# haltium_cellcore register map
Vendor: Nordic Semiconductor; Series: nRFHaltium; File version: 1
CPU: CM33 r0p4, little endian, MPU, FPU, 3 interrupt priority bits, 480 interrupts
Registers are 32-bit, read-write, reset 0x0 unless marked. A register's access mark holds for its fields unless they carry their own. Offsets are from the block's base; [hi:lo] are bit positions; lines under a group give offsets from that group; {n}, {i} and the like mark numbered series.

## RAMC00_NS — RAM Controller 0
Base 0x44006000
Same registers: RAMC00_S 0x54006000
0x500 WAITSTATES — Waitstates for read operations.
  [0] WAITSTATES — Number of waitstates for a read from the RAM.
0x600 SECBASE — Base address for secure access area.
  [31:0] ADDR — Base address
0x604 SECENABLE — Enable secure access restrictions.
  [0] ENABLE — Enable secure access restrictions
    0=Disable (Secure access restrictions disabled); 1=Enable (Secure access restrictions enabled)

## TRACEDELAYREG_NS — Trace delay register 0
Base 0x4400B000
Same registers: TRACEDELAYREG_S 0x5400B000
0x504 DELAYREGCONFIG — Configuration register for DELAYREG delay
  [4:0] DELAYREGCONFIG — Register write delay, configurable between 0 and 31 clock cycles. Delay between apbPEnable and apbPReady is adjusted to the configured value, except for the small values, when minimum interconnect delay exist.
0x600 DELAYREG wo — Dummy register with adjustable write delay. Occupies 0x100 address range i.e. 256bytes. This space emulates the extended stimulus port area of ARM Coresight STM.
  [31:0] DELAYREG — Dummy register with adjustable write delay

## PCGCS0_S — PCGCSlave 0
Base 0x5400C000
Same registers: PCGCS1_S 0x54018000, PCGCS3_S 0x54036000
0x78 TRIGZEROPENALTY — Trigger zero penalty
  [0] TRIGGER
    1=Enable (Trigger zero penalty)
0x7C TRIGFULLPENALTY — Trigger full penalty
  [0] TRIGGER
    1=Enable (Trigger full penalty)
{0xC00+4i} PENALTY[{i}] (i=0..1) — Description collection: Penalty level for power/clock pair n
  [7:0] PENALTY — Penalty level
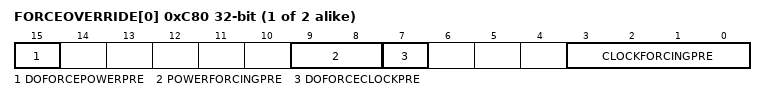
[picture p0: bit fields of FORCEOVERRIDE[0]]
{0xC80+4i} FORCEOVERRIDE[{i}] (i=0..1) — Description collection: Force override of power/clock pair n
  [15] DOFORCEPOWERPRE, [9:8] POWERFORCINGPRE, [7] DOFORCECLOCKPRE, [3:0] CLOCKFORCINGPRE

## PCGCM0_S — PCGC Master 0
Base 0x5400D000
Same registers: PCGCM1_S 0x54019000, PCGCM3_S 0x54037000
{0xE0+4i} SETPWRCONTHRESHOLDBASE[{i}] (i=0..2) — Description collection: Set power consumption threshold base for power source / regulator n
  [3:0] SETPWRCONTHRESHOLDBASE
{0x100+4i} SETPOWERCONSUMPTIONBASE[{i}] (i=0..1) — Description collection: Set power consumption base for power/clock pair n
  [3:0] POWERREQUIREMENT
0xC00 UNLOCKBACKDOORS
  [15:0] UNLOCKBACKDOORS — Write: 0x00009375 to lock/unlock backdoors Read: 0x00000001 if backdoors is enabled Read: 0x00000000 if backdoors is disabled
0xC04 ENABLEPOWERREGFORCE
  [2:0] ENABLEPOWERREGFORCE
0xC08 POWERREGFORCE — Force reg
  [2:0] POWERREGFORCEREG
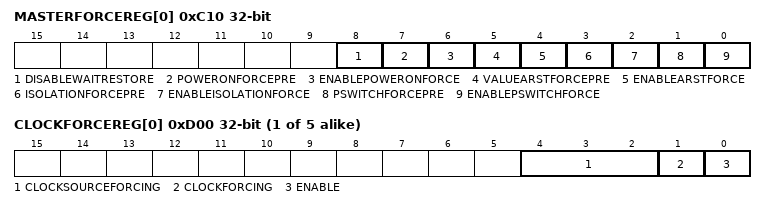
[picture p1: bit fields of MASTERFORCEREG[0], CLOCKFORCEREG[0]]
{0xC10+4i} MASTERFORCEREG[{i}] (i=0..0) — Description collection: Force reg
  [8] DISABLEWAITRESTORE — Turn off waiting for arst deactivation before retention restore
    1=Disable (Turn off waiting for arst deactivation before retention restore); 0=Enable (Wait for arst deactivation before retention restore)
  [7] POWERONFORCEPRE
  [6] ENABLEPOWERONFORCE
  [5] VALUEARSTFORCEPRE
  [4] ENABLEARSTFORCE
  [3] ISOLATIONFORCEPRE
  [2] ENABLEISOLATIONFORCE
  [1] PSWITCHFORCEPRE
  [0] ENABLEPSWITCHFORCE
{0xD00+4i} CLOCKFORCEREG[{i}] (i=0..4) — Description collection: Force clock n
  [4:2] CLOCKSOURCEFORCING
  [1] CLOCKFORCING
  [0] ENABLE — Enable clock forcing

## RESETINFO_S — RESETINFO
Base 0x54011000; alternate view of LRCCONF1_S
0x4A0 RESETREAS group — Unspecified
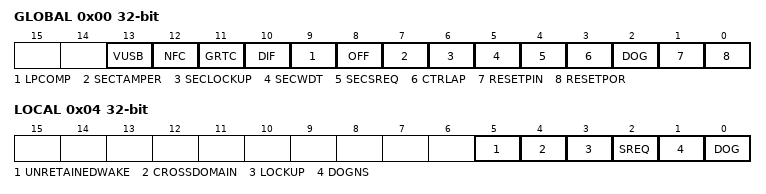
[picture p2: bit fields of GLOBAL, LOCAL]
  0x00 GLOBAL — Global reset reason.
    [all] fields
      0=NotDetected; 1=Detected
    [13] VUSB — Reset after wakeup from System OFF mode due to VBUS rising into valid range.
    [12] NFC — Reset due to wakeup from System OFF mode when wakeup is triggered by NFC field detection in sense mode.
    [11] GRTC — Reset due to wakeup from System OFF mode when wakeup is triggered by GRTC interrupt.
    [10] DIF — Reset due to wakeup from System OFF mode when wakeup is triggered by entering the debug interface mode.
    [9] LPCOMP — Reset due to wakeup from System OFF mode when wakeup is triggered by LPCOMP (Low Power Comparator).
    [8] OFF — Reset due to wakeup from System OFF mode when wakeup is triggered by DETECT signal from GPIO.
    [7] SECTAMPER — Reset due to secure domain tamper detected
    [6] SECLOCKUP — Reset due to secure domain lockup.
    [5] SECWDT — Reset due to secure domain watchdog timer detected.
    [4] SECSREQ — Reset due to secure domain system reset request.
    [3] CTRLAP — Reset from CTRL-AP detected.
    [2] DOG — Reset from the SysCtrl watchdog timer detected.
    [1] RESETPIN — Reset from pin reset detected.
    [0] RESETPOR — Reset from power on reset.
  0x04 LOCAL — Local reset reason.
    [5] UNRETAINEDWAKE — Reset due to wake from unretained state.
    [4] CROSSDOMAIN — Reset due to cross domain reset source.
      0=NotDetected; 1=Detected
    [3] LOCKUP — Reset from local CPU lockup detected
      0=NotDetected; 1=Detected
    [2] SREQ — Reset from the local soft reset request detected.
      0=NotDetected; 1=Detected
    [1] DOGNS — Reset from the local non-secure watchdog timer detected
      0=NotDetected; 1=Detected
    [0] DOG — Reset from the local watchdog timer detected
      0=NotDetected; 1=Detected
  0x08 ERROR group — Unspecified
    0x00 STATUS — Reset error status.
      [3:0] ERRORSTATUS
    0x04 ADDRESS — Reset error address.
      [31:0] ERRORADDRESS
0x4C0 RESTOREVALID write-1-clears — Valid restore image is present in RAM.
  [0] RESTOREVALID
    0=NotPreset (Not present); 1=Present
0x4C4 MASKLOCKUP — Mask CPU lockup signal.
  [0] MASK — Mask lockup signal
    0=NotMask (Do not mask lockup signal); 1=Mask lockup signal
